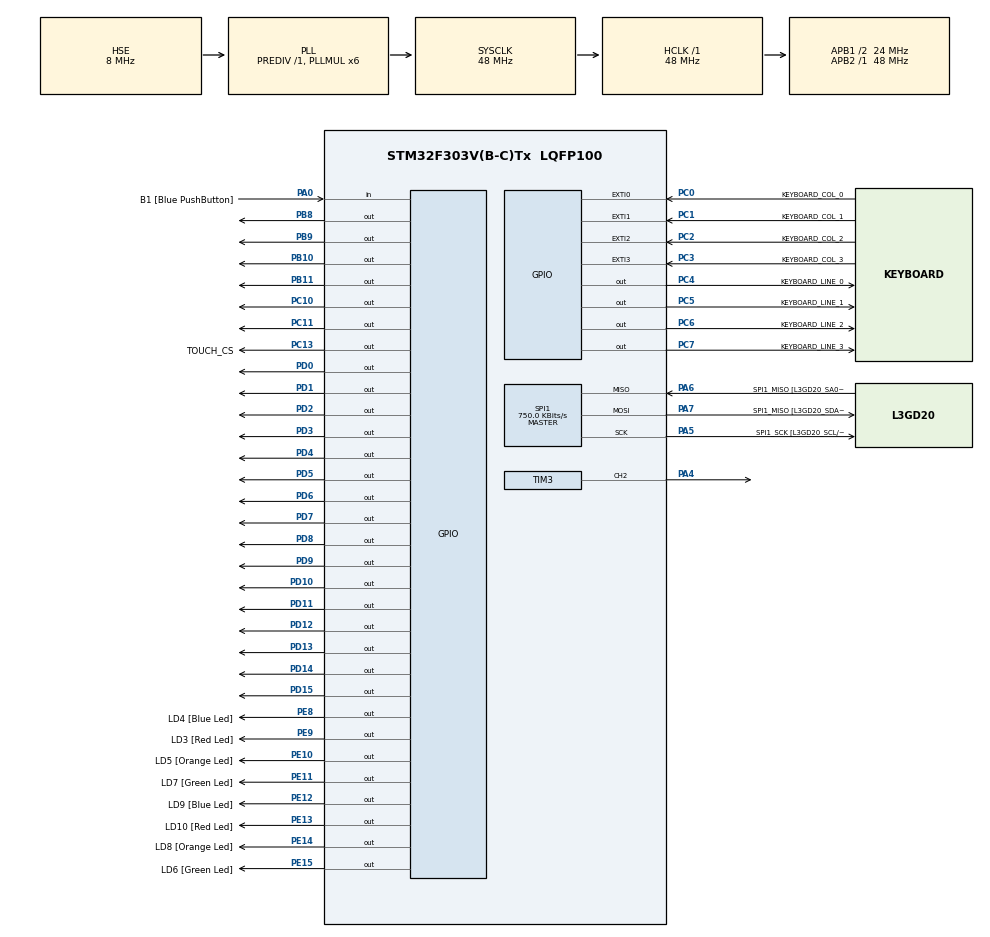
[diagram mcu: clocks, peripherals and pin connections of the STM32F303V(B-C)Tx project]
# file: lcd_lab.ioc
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Mcu.Family=STM32F3
Mcu.Name=STM32F303V(B-C)Tx
Mcu.Package=LQFP100
NVIC.EXTI0_IRQn=true\:0\:4\:false\:false\:true\:true\:true\:true
NVIC.EXTI1_IRQn=true\:0\:4\:false\:false\:true\:true\:true\:true
NVIC.EXTI2_TSC_IRQn=true\:0\:4\:false\:false\:true\:true\:true\:true
NVIC.EXTI3_IRQn=true\:0\:4\:false\:false\:true\:true\:true\:true
NVIC.PriorityGroup=NVIC_PRIORITYGROUP_0
PA0.GPIO_Label=B1 [Blue PushButton]
PA0.GPIO_Mode=GPIO_MODE_INPUT
PA0.GPIO_PuPd=GPIO_NOPULL
PA0.Signal=GPIO_Input
PA13.GPIO_Label=SWDIO
PA13.Mode=Trace_Asynchronous_SW
PA13.Signal=SYS_JTMS-SWDIO
PA14.GPIO_Label=SWCLK
PA14.Mode=Trace_Asynchronous_SW
PA14.Signal=SYS_JTCK-SWCLK
PA4.Signal=S_TIM3_CH2
PA5.GPIO_Label=SPI1_SCK [L3GD20_SCL/SPC]
PA5.GPIO_Mode=GPIO_MODE_AF_PP
PA5.GPIO_PuPd=GPIO_NOPULL
PA5.GPIO_Speed=GPIO_SPEED_FREQ_LOW
PA5.Mode=Full_Duplex_Master
PA5.Signal=SPI1_SCK
PA6.GPIO_Label=SPI1_MISO [L3GD20_SA0/SDO]
PA6.GPIO_Mode=GPIO_MODE_AF_PP
PA6.GPIO_PuPd=GPIO_NOPULL
PA6.GPIO_Speed=GPIO_SPEED_FREQ_LOW
PA6.Mode=Full_Duplex_Master
PA6.Signal=SPI1_MISO
PA7.GPIO_Label=SPI1_MISO [L3GD20_SDA/SDI/SDO]
PA7.GPIO_Mode=GPIO_MODE_AF_PP
PA7.GPIO_PuPd=GPIO_NOPULL
PA7.GPIO_Speed=GPIO_SPEED_FREQ_LOW
PA7.Mode=Full_Duplex_Master
PA7.Signal=SPI1_MOSI
PB10.GPIO_Speed=GPIO_SPEED_FREQ_HIGH
PB10.PinState=GPIO_PIN_SET
PB10.Signal=GPIO_Output
PB11.GPIO_Speed=GPIO_SPEED_FREQ_HIGH
PB11.PinState=GPIO_PIN_SET
PB11.Signal=GPIO_Output
PB3.GPIO_Label=SWO
PB3.Mode=Trace_Asynchronous_SW
PB3.Signal=SYS_JTDO-TRACESWO
PB8.GPIO_Speed=GPIO_SPEED_FREQ_HIGH
PB8.PinState=GPIO_PIN_SET
PB8.Signal=GPIO_Output
PB9.GPIO_Speed=GPIO_SPEED_FREQ_HIGH
PB9.PinState=GPIO_PIN_SET
PB9.Signal=GPIO_Output
PC0.GPIO_Label=KEYBOARD_COL_0
PC0.GPIO_ModeDefaultEXTI=GPIO_MODE_IT_RISING_FALLING
PC0.GPIO_PuPd=GPIO_PULLDOWN
PC0.Signal=GPXTI0
PC1.GPIO_Label=KEYBOARD_COL_1
PC1.GPIO_ModeDefaultEXTI=GPIO_MODE_IT_RISING_FALLING
PC1.GPIO_PuPd=GPIO_PULLDOWN
PC1.Signal=GPXTI1
PC10.GPIO_ModeDefaultOutputPP=GPIO_MODE_OUTPUT_OD
PC10.GPIO_PuPd=GPIO_PULLUP
PC10.GPIO_Speed=GPIO_SPEED_FREQ_HIGH
PC10.PinState=GPIO_PIN_SET
PC10.Signal=GPIO_Output
PC11.GPIO_ModeDefaultOutputPP=GPIO_MODE_OUTPUT_OD
PC11.GPIO_PuPd=GPIO_PULLUP
PC11.GPIO_Speed=GPIO_SPEED_FREQ_HIGH
PC11.PinState=GPIO_PIN_SET
PC11.Signal=GPIO_Output
PC13.GPIO_Label=TOUCH_CS
PC13.GPIO_ModeDefaultOutputPP=GPIO_MODE_OUTPUT_OD
PC13.GPIO_PuPd=GPIO_PULLUP
PC13.PinState=GPIO_PIN_SET
PC13.Signal=GPIO_Output
PC14-OSC32_IN.GPIO_Label=OSC32_IN
PC14-OSC32_IN.Signal=RCC_OSC32_IN
PC15-OSC32_OUT.GPIO_Label=OSC32_OUT
PC15-OSC32_OUT.Signal=RCC_OSC32_OUT
PC2.GPIO_Label=KEYBOARD_COL_2
PC2.GPIO_ModeDefaultEXTI=GPIO_MODE_IT_RISING_FALLING
PC2.GPIO_PuPd=GPIO_PULLDOWN
PC2.Signal=GPXTI2
PC3.GPIO_Label=KEYBOARD_COL_3
PC3.GPIO_ModeDefaultEXTI=GPIO_MODE_IT_RISING_FALLING
PC3.GPIO_PuPd=GPIO_PULLDOWN
PC3.Signal=GPXTI3
PC4.GPIO_Label=KEYBOARD_LINE_0
PC4.GPIO_Speed=GPIO_SPEED_FREQ_HIGH
PC4.PinState=GPIO_PIN_SET
PC4.Signal=GPIO_Output
PC5.GPIO_Label=KEYBOARD_LINE_1
PC5.GPIO_Speed=GPIO_SPEED_FREQ_HIGH
PC5.PinState=GPIO_PIN_SET
PC5.Signal=GPIO_Output
PC6.GPIO_Label=KEYBOARD_LINE_2
PC6.GPIO_Speed=GPIO_SPEED_FREQ_HIGH
PC6.PinState=GPIO_PIN_SET
PC6.Signal=GPIO_Output
PC7.GPIO_Label=KEYBOARD_LINE_3
PC7.GPIO_Speed=GPIO_SPEED_FREQ_HIGH
PC7.PinState=GPIO_PIN_SET
PC7.Signal=GPIO_Output
PD0.GPIO_Speed=GPIO_SPEED_FREQ_HIGH
PD0.PinState=GPIO_PIN_SET
PD0.Signal=GPIO_Output
PD1.GPIO_Speed=GPIO_SPEED_FREQ_HIGH
PD1.PinState=GPIO_PIN_SET
PD1.Signal=GPIO_Output
PD10.GPIO_Speed=GPIO_SPEED_FREQ_HIGH
PD10.PinState=GPIO_PIN_SET
PD10.Signal=GPIO_Output
PD11.GPIO_Speed=GPIO_SPEED_FREQ_HIGH
PD11.PinState=GPIO_PIN_SET
PD11.Signal=GPIO_Output
PD12.GPIO_Speed=GPIO_SPEED_FREQ_HIGH
PD12.PinState=GPIO_PIN_SET
PD12.Signal=GPIO_Output
PD13.GPIO_Speed=GPIO_SPEED_FREQ_HIGH
PD13.PinState=GPIO_PIN_SET
PD13.Signal=GPIO_Output
PD14.GPIO_Speed=GPIO_SPEED_FREQ_HIGH
PD14.PinState=GPIO_PIN_SET
PD14.Signal=GPIO_Output
PD15.GPIO_Speed=GPIO_SPEED_FREQ_HIGH
PD15.PinState=GPIO_PIN_SET
PD15.Signal=GPIO_Output
PD2.GPIO_Speed=GPIO_SPEED_FREQ_HIGH
PD2.PinState=GPIO_PIN_SET
PD2.Signal=GPIO_Output
PD3.GPIO_Speed=GPIO_SPEED_FREQ_HIGH
PD3.PinState=GPIO_PIN_SET
PD3.Signal=GPIO_Output
PD4.GPIO_Speed=GPIO_SPEED_FREQ_HIGH
PD4.PinState=GPIO_PIN_SET
PD4.Signal=GPIO_Output
PD5.GPIO_Speed=GPIO_SPEED_FREQ_HIGH
PD5.PinState=GPIO_PIN_SET
PD5.Signal=GPIO_Output
PD6.GPIO_Speed=GPIO_SPEED_FREQ_HIGH
PD6.PinState=GPIO_PIN_SET
PD6.Signal=GPIO_Output
PD7.GPIO_Speed=GPIO_SPEED_FREQ_HIGH
PD7.PinState=GPIO_PIN_SET
PD7.Signal=GPIO_Output
PD8.GPIO_Speed=GPIO_SPEED_FREQ_HIGH
PD8.PinState=GPIO_PIN_SET
PD8.Signal=GPIO_Output
PD9.GPIO_Speed=GPIO_SPEED_FREQ_HIGH
PD9.PinState=GPIO_PIN_SET
PD9.Signal=GPIO_Output
PE10.GPIO_Label=LD5 [Orange Led]
PE10.GPIO_ModeDefaultOutputPP=GPIO_MODE_OUTPUT_PP
PE10.GPIO_PuPd=GPIO_NOPULL
PE10.GPIO_Speed=GPIO_SPEED_FREQ_LOW
PE10.Signal=GPIO_Output
PE11.GPIO_Label=LD7 [Green Led]
PE11.GPIO_ModeDefaultOutputPP=GPIO_MODE_OUTPUT_PP
PE11.GPIO_PuPd=GPIO_NOPULL
PE11.GPIO_Speed=GPIO_SPEED_FREQ_LOW
PE11.Signal=GPIO_Output
PE12.GPIO_Label=LD9 [Blue Led]
PE12.GPIO_ModeDefaultOutputPP=GPIO_MODE_OUTPUT_PP
PE12.GPIO_PuPd=GPIO_NOPULL
PE12.GPIO_Speed=GPIO_SPEED_FREQ_LOW
PE12.Signal=GPIO_Output
PE13.GPIO_Label=LD10 [Red Led]
PE13.GPIO_ModeDefaultOutputPP=GPIO_MODE_OUTPUT_PP
PE13.GPIO_PuPd=GPIO_NOPULL
PE13.GPIO_Speed=GPIO_SPEED_FREQ_LOW
PE13.Signal=GPIO_Output
PE14.GPIO_Label=LD8 [Orange Led]
PE14.GPIO_ModeDefaultOutputPP=GPIO_MODE_OUTPUT_PP
PE14.GPIO_PuPd=GPIO_NOPULL
PE14.GPIO_Speed=GPIO_SPEED_FREQ_LOW
PE14.Signal=GPIO_Output
PE15.GPIO_Label=LD6 [Green Led]
PE15.GPIO_ModeDefaultOutputPP=GPIO_MODE_OUTPUT_PP
PE15.GPIO_PuPd=GPIO_NOPULL
PE15.GPIO_Speed=GPIO_SPEED_FREQ_LOW
PE15.Signal=GPIO_Output
PE8.GPIO_Label=LD4 [Blue Led]
PE8.GPIO_ModeDefaultOutputPP=GPIO_MODE_OUTPUT_PP
PE8.GPIO_PuPd=GPIO_NOPULL
PE8.GPIO_Speed=GPIO_SPEED_FREQ_LOW
PE8.Signal=GPIO_Output
PE9.GPIO_Label=LD3 [Red Led]
PE9.GPIO_ModeDefaultOutputPP=GPIO_MODE_OUTPUT_PP
PE9.GPIO_PuPd=GPIO_NOPULL
PE9.GPIO_Speed=GPIO_SPEED_FREQ_LOW
PE9.Signal=GPIO_Output
PF0-OSC_IN.GPIO_Label=OSC_IN
PF0-OSC_IN.Mode=HSE-External-Clock-Source
PF0-OSC_IN.Signal=RCC_OSC_IN
PF1-OSC_OUT.GPIO_Label=OSC_OUT
PF1-OSC_OUT.Signal=RCC_OSC_OUT
ProjectManager.HeapSize=0x400
ProjectManager.StackSize=0x4000
ProjectManager.TargetToolchain=STM32CubeIDE
RCC.AHBFreq_Value=48000000
RCC.APB1CLKDivider=RCC_HCLK_DIV2
RCC.APB1Freq_Value=24000000
RCC.APB1TimFreq_Value=48000000
RCC.APB2Freq_Value=48000000
RCC.APB2TimFreq_Value=48000000
RCC.CortexFreq_Value=48000000
RCC.HCLKFreq_Value=48000000
RCC.HSE_VALUE=8000000
RCC.HSI_VALUE=8000000
RCC.LSE_VALUE=32768
RCC.PLLMUL=RCC_PLL_MUL6
RCC.PLLSourceVirtual=RCC_PLLSOURCE_HSE
RCC.SYSCLKFreq_VALUE=48000000
RCC.SYSCLKSourceVirtual=RCC_SYSCLKSOURCE_PLLCLK
RCC.USBFreq_Value=48000000
SH.S_TIM3_CH2.0=TIM3_CH2,PWM Generation2 CH2
SPI1.BaudRatePrescaler=SPI_BAUDRATEPRESCALER_64
SPI1.CalculateBaudRate=750.0 KBits/s
SPI1.DataSize=SPI_DATASIZE_8BIT
SPI1.Direction=SPI_DIRECTION_2LINES
SPI1.Mode=SPI_MODE_MASTER
SPI1.VirtualType=VM_MASTER
TIM3.AutoReloadPreload=TIM_AUTORELOAD_PRELOAD_ENABLE
TIM3.Channel-PWM\ Generation2\ CH2=TIM_CHANNEL_2
TIM3.Period=999
TIM3.Prescaler=47
TIM3.Pulse-PWM\ Generation2\ CH2=500
board=STM32F3DISCOVERY

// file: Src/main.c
/* USER CODE BEGIN Header */
/**
 ******************************************************************************
 * @file           : main.c
 * @brief          : Main program body
 ******************************************************************************
 * @attention
 *
 * Copyright (c) 2022 STMicroelectronics.
 * All rights reserved.
 *
 * This software is licensed under terms that can be found in the LICENSE file
 * in the root directory of this software component.
 * If no LICENSE file comes with this software, it is provided AS-IS.
 *
 ******************************************************************************
 */
/* USER CODE END Header */
#include "main.h"

/* USER CODE BEGIN Includes */
#include <stdlib.h>
#include <string.h>

#include "driver.h"
#include "keyboard.h"
#include "lab_5_icons.h"
#include "lvgl.h"

#include "app.h"
/* USER CODE END Includes */

 SPI_HandleTypeDef hspi1;

TIM_HandleTypeDef htim3;

void SystemClock_Config(void);
static void MX_GPIO_Init(void);
static void MX_SPI1_Init(void);
static void MX_TIM3_Init(void);

int main(void)
{

  /* MCU Configuration--------------------------------------------------------*/

  /* Reset of all peripherals, Initializes the Flash interface and the Systick. */
  HAL_Init();

  /* Configure the system clock */
  SystemClock_Config();

  /* Initialize all configured peripherals */
  MX_GPIO_Init();
  MX_SPI1_Init();
  MX_TIM3_Init();
  /* USER CODE BEGIN 2 */

  App *app = App_new();
  while (!app) {
    __NOP();
  }

  // Keyboard_Init();
  // Keyboard_SetCallback(KeyboardHandleEvent);

  /* USER CODE END 2 */

  /* Infinite loop */
  /* USER CODE BEGIN WHILE */
  while (1) {
    App_update(app);
    /* USER CODE END WHILE */

    /* USER CODE BEGIN 3 */
    HAL_Delay(1);
  }
  /* USER CODE END 3 */
}

void SystemClock_Config(void)
{
  RCC_OscInitTypeDef RCC_OscInitStruct = {0};
  RCC_ClkInitTypeDef RCC_ClkInitStruct = {0};

  /** Initializes the RCC Oscillators according to the specified parameters
  * in the RCC_OscInitTypeDef structure.
  */
  RCC_OscInitStruct.OscillatorType = RCC_OSCILLATORTYPE_HSE;
  RCC_OscInitStruct.HSEState = RCC_HSE_BYPASS;
  RCC_OscInitStruct.HSEPredivValue = RCC_HSE_PREDIV_DIV1;
  RCC_OscInitStruct.HSIState = RCC_HSI_ON;
  RCC_OscInitStruct.PLL.PLLState = RCC_PLL_ON;
  RCC_OscInitStruct.PLL.PLLSource = RCC_PLLSOURCE_HSE;
  RCC_OscInitStruct.PLL.PLLMUL = RCC_PLL_MUL6;
  if (HAL_RCC_OscConfig(&RCC_OscInitStruct) != HAL_OK)
  {
    Error_Handler();
  }

  /** Initializes the CPU, AHB and APB buses clocks
  */
  RCC_ClkInitStruct.ClockType = RCC_CLOCKTYPE_HCLK|RCC_CLOCKTYPE_SYSCLK
                              |RCC_CLOCKTYPE_PCLK1|RCC_CLOCKTYPE_PCLK2;
  RCC_ClkInitStruct.SYSCLKSource = RCC_SYSCLKSOURCE_PLLCLK;
  RCC_ClkInitStruct.AHBCLKDivider = RCC_SYSCLK_DIV1;
  RCC_ClkInitStruct.APB1CLKDivider = RCC_HCLK_DIV2;
  RCC_ClkInitStruct.APB2CLKDivider = RCC_HCLK_DIV1;

  if (HAL_RCC_ClockConfig(&RCC_ClkInitStruct, FLASH_LATENCY_1) != HAL_OK)
  {
    Error_Handler();
  }
}

static void MX_SPI1_Init(void)
{

  /* SPI1 parameter configuration*/
  hspi1.Instance = SPI1;
  hspi1.Init.Mode = SPI_MODE_MASTER;
  hspi1.Init.Direction = SPI_DIRECTION_2LINES;
  hspi1.Init.DataSize = SPI_DATASIZE_8BIT;
  hspi1.Init.CLKPolarity = SPI_POLARITY_LOW;
  hspi1.Init.CLKPhase = SPI_PHASE_1EDGE;
  hspi1.Init.NSS = SPI_NSS_SOFT;
  hspi1.Init.BaudRatePrescaler = SPI_BAUDRATEPRESCALER_64;
  hspi1.Init.FirstBit = SPI_FIRSTBIT_MSB;
  hspi1.Init.TIMode = SPI_TIMODE_DISABLE;
  hspi1.Init.CRCCalculation = SPI_CRCCALCULATION_DISABLE;
  hspi1.Init.CRCPolynomial = 7;
  hspi1.Init.CRCLength = SPI_CRC_LENGTH_DATASIZE;
  hspi1.Init.NSSPMode = SPI_NSS_PULSE_ENABLE;
  if (HAL_SPI_Init(&hspi1) != HAL_OK)
  {
    Error_Handler();
  }

}

static void MX_TIM3_Init(void)
{

  TIM_MasterConfigTypeDef sMasterConfig = {0};
  TIM_OC_InitTypeDef sConfigOC = {0};

  htim3.Instance = TIM3;
  htim3.Init.Prescaler = 47;
  htim3.Init.CounterMode = TIM_COUNTERMODE_UP;
  htim3.Init.Period = 999;
  htim3.Init.ClockDivision = TIM_CLOCKDIVISION_DIV1;
  htim3.Init.AutoReloadPreload = TIM_AUTORELOAD_PRELOAD_ENABLE;
  if (HAL_TIM_PWM_Init(&htim3) != HAL_OK)
  {
    Error_Handler();
  }
  sMasterConfig.MasterOutputTrigger = TIM_TRGO_RESET;
  sMasterConfig.MasterSlaveMode = TIM_MASTERSLAVEMODE_DISABLE;
  if (HAL_TIMEx_MasterConfigSynchronization(&htim3, &sMasterConfig) != HAL_OK)
  {
    Error_Handler();
  }
  sConfigOC.OCMode = TIM_OCMODE_PWM1;
  sConfigOC.Pulse = 500;
  sConfigOC.OCPolarity = TIM_OCPOLARITY_HIGH;
  sConfigOC.OCFastMode = TIM_OCFAST_DISABLE;
  if (HAL_TIM_PWM_ConfigChannel(&htim3, &sConfigOC, TIM_CHANNEL_2) != HAL_OK)
  {
    Error_Handler();
  }
  HAL_TIM_MspPostInit(&htim3);

}

static void MX_GPIO_Init(void)
{
  GPIO_InitTypeDef GPIO_InitStruct = {0};

  /* GPIO Ports Clock Enable */
  __HAL_RCC_GPIOC_CLK_ENABLE();
  __HAL_RCC_GPIOF_CLK_ENABLE();
  __HAL_RCC_GPIOA_CLK_ENABLE();
  __HAL_RCC_GPIOE_CLK_ENABLE();
  __HAL_RCC_GPIOB_CLK_ENABLE();
  __HAL_RCC_GPIOD_CLK_ENABLE();

  /*Configure GPIO pin Output Level */
  HAL_GPIO_WritePin(GPIOC, TOUCH_CS_Pin|KEYBOARD_LINE_0_Pin|KEYBOARD_LINE_1_Pin|KEYBOARD_LINE_2_Pin
                          |KEYBOARD_LINE_3_Pin|GPIO_PIN_10|GPIO_PIN_11, GPIO_PIN_SET);

  /*Configure GPIO pin Output Level */
  HAL_GPIO_WritePin(GPIOE, LD4_Pin|LD3_Pin|LD5_Pin|LD7_Pin
                          |LD9_Pin|LD10_Pin|LD8_Pin|LD6_Pin, GPIO_PIN_RESET);

  /*Configure GPIO pin Output Level */
  HAL_GPIO_WritePin(GPIOB, GPIO_PIN_10|GPIO_PIN_11|GPIO_PIN_8|GPIO_PIN_9, GPIO_PIN_SET);

  /*Configure GPIO pin Output Level */
  HAL_GPIO_WritePin(GPIOD, GPIO_PIN_8|GPIO_PIN_9|GPIO_PIN_10|GPIO_PIN_11
                          |GPIO_PIN_12|GPIO_PIN_13|GPIO_PIN_14|GPIO_PIN_15
                          |GPIO_PIN_0|GPIO_PIN_1|GPIO_PIN_2|GPIO_PIN_3
                          |GPIO_PIN_4|GPIO_PIN_5|GPIO_PIN_6|GPIO_PIN_7, GPIO_PIN_SET);

  /*Configure GPIO pin : TOUCH_CS_Pin */
  GPIO_InitStruct.Pin = TOUCH_CS_Pin;
  GPIO_InitStruct.Mode = GPIO_MODE_OUTPUT_OD;
  GPIO_InitStruct.Pull = GPIO_PULLUP;
  GPIO_InitStruct.Speed = GPIO_SPEED_FREQ_LOW;
  HAL_GPIO_Init(TOUCH_CS_GPIO_Port, &GPIO_InitStruct);

  /*Configure GPIO pins : KEYBOARD_COL_0_Pin KEYBOARD_COL_1_Pin KEYBOARD_COL_2_Pin KEYBOARD_COL_3_Pin */
  GPIO_InitStruct.Pin = KEYBOARD_COL_0_Pin|KEYBOARD_COL_1_Pin|KEYBOARD_COL_2_Pin|KEYBOARD_COL_3_Pin;
  GPIO_InitStruct.Mode = GPIO_MODE_IT_RISING_FALLING;
  GPIO_InitStruct.Pull = GPIO_PULLDOWN;
  HAL_GPIO_Init(GPIOC, &GPIO_InitStruct);

  /*Configure GPIO pin : B1_Pin */
  GPIO_InitStruct.Pin = B1_Pin;
  GPIO_InitStruct.Mode = GPIO_MODE_INPUT;
  GPIO_InitStruct.Pull = GPIO_NOPULL;
  HAL_GPIO_Init(B1_GPIO_Port, &GPIO_InitStruct);

  /*Configure GPIO pins : KEYBOARD_LINE_0_Pin KEYBOARD_LINE_1_Pin KEYBOARD_LINE_2_Pin KEYBOARD_LINE_3_Pin */
  GPIO_InitStruct.Pin = KEYBOARD_LINE_0_Pin|KEYBOARD_LINE_1_Pin|KEYBOARD_LINE_2_Pin|KEYBOARD_LINE_3_Pin;
  GPIO_InitStruct.Mode = GPIO_MODE_OUTPUT_PP;
  GPIO_InitStruct.Pull = GPIO_NOPULL;
  GPIO_InitStruct.Speed = GPIO_SPEED_FREQ_HIGH;
  HAL_GPIO_Init(GPIOC, &GPIO_InitStruct);

  /*Configure GPIO pins : LD4_Pin LD3_Pin LD5_Pin LD7_Pin
                           LD9_Pin LD10_Pin LD8_Pin LD6_Pin */
  GPIO_InitStruct.Pin = LD4_Pin|LD3_Pin|LD5_Pin|LD7_Pin
                          |LD9_Pin|LD10_Pin|LD8_Pin|LD6_Pin;
  GPIO_InitStruct.Mode = GPIO_MODE_OUTPUT_PP;
  GPIO_InitStruct.Pull = GPIO_NOPULL;
  GPIO_InitStruct.Speed = GPIO_SPEED_FREQ_LOW;
  HAL_GPIO_Init(GPIOE, &GPIO_InitStruct);

  /*Configure GPIO pins : PB10 PB11 PB8 PB9 */
  GPIO_InitStruct.Pin = GPIO_PIN_10|GPIO_PIN_11|GPIO_PIN_8|GPIO_PIN_9;
  GPIO_InitStruct.Mode = GPIO_MODE_OUTPUT_PP;
  GPIO_InitStruct.Pull = GPIO_NOPULL;
  GPIO_InitStruct.Speed = GPIO_SPEED_FREQ_HIGH;
  HAL_GPIO_Init(GPIOB, &GPIO_InitStruct);

  /*Configure GPIO pins : PD8 PD9 PD10 PD11
                           PD12 PD13 PD14 PD15
                           PD0 PD1 PD2 PD3
                           PD4 PD5 PD6 PD7 */
  GPIO_InitStruct.Pin = GPIO_PIN_8|GPIO_PIN_9|GPIO_PIN_10|GPIO_PIN_11
                          |GPIO_PIN_12|GPIO_PIN_13|GPIO_PIN_14|GPIO_PIN_15
                          |GPIO_PIN_0|GPIO_PIN_1|GPIO_PIN_2|GPIO_PIN_3
                          |GPIO_PIN_4|GPIO_PIN_5|GPIO_PIN_6|GPIO_PIN_7;
  GPIO_InitStruct.Mode = GPIO_MODE_OUTPUT_PP;
  GPIO_InitStruct.Pull = GPIO_NOPULL;
  GPIO_InitStruct.Speed = GPIO_SPEED_FREQ_HIGH;
  HAL_GPIO_Init(GPIOD, &GPIO_InitStruct);

  /*Configure GPIO pins : PC10 PC11 */
  GPIO_InitStruct.Pin = GPIO_PIN_10|GPIO_PIN_11;
  GPIO_InitStruct.Mode = GPIO_MODE_OUTPUT_OD;
  GPIO_InitStruct.Pull = GPIO_PULLUP;
  GPIO_InitStruct.Speed = GPIO_SPEED_FREQ_HIGH;
  HAL_GPIO_Init(GPIOC, &GPIO_InitStruct);

  /* EXTI interrupt init*/
  HAL_NVIC_SetPriority(EXTI0_IRQn, 0, 4);
  HAL_NVIC_EnableIRQ(EXTI0_IRQn);

  HAL_NVIC_SetPriority(EXTI1_IRQn, 0, 4);
  HAL_NVIC_EnableIRQ(EXTI1_IRQn);

  HAL_NVIC_SetPriority(EXTI2_TSC_IRQn, 0, 4);
  HAL_NVIC_EnableIRQ(EXTI2_TSC_IRQn);

  HAL_NVIC_SetPriority(EXTI3_IRQn, 0, 4);
  HAL_NVIC_EnableIRQ(EXTI3_IRQn);

}

void Error_Handler(void)
{
  __disable_irq();
  while (1) {
  }
}

#ifdef  USE_FULL_ASSERT
/**
  * @brief  Reports the name of the source file and the source line number
  *         where the assert_param error has occurred.
  * @param  file: pointer to the source file name
  * @param  line: assert_param error line source number
  * @retval None
  */
void assert_failed(uint8_t *file, uint32_t line)
{
  /* USER CODE BEGIN 6 */
  /* User can add his own implementation to report the file name and line
     number,
     ex: printf("Wrong parameters value: file %s on line %d\r\n", file, line) */
  /* USER CODE END 6 */
}
#endif /* USE_FULL_ASSERT */
